# ATtiny20 register map
Vendor: Atmel; File version: 1.0
CPU: other r0p0, little endian, no MPU, no FPU, 4 interrupt priority bits
Registers are 8-bit, read-write, reset 0x0 unless marked. A register's access mark holds for its fields unless they carry their own. Offsets are from the block's base; [hi:lo] are bit positions; {n}, {i} and the like mark numbered series.

## EXINT — External Interrupts
Base 0x00800009
0x00 PCMSK0 — Pin Change Mask Register 0
  [7:0] PCINT — Pin Change Enable Masks
0x01 PCMSK1 — Pin Change Mask Register 1
  [3:0] PCINT — Pin Change Enable Masks
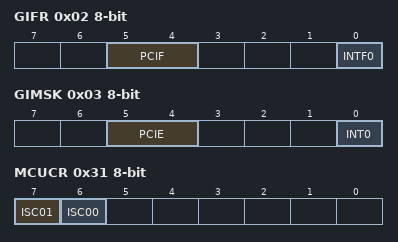
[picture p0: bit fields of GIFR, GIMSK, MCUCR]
0x02 GIFR — General Interrupt Flag Register
  [5:4] PCIF — Pin Change Interrupt Flags
  [0] INTF0 — External Interrupt Flag 0
0x03 GIMSK — General Interrupt Mask Register
  [5:4] PCIE — Pin Change Interrupt Enables
  [0] INT0 — External Interrupt Request 0 Enable
0x31 MCUCR — MCU Control Register
  [7] ISC01 — Interrupt Sense Control 0 Bit 1
  [6] ISC00 — Interrupt Sense Control 0 Bit 0
    0=LOW_LEVEL_OF_INTX; 1=ANY_LOGICAL_CHANGE_ON_INTX

## PORTA — I/O Port
Base 0x00800000
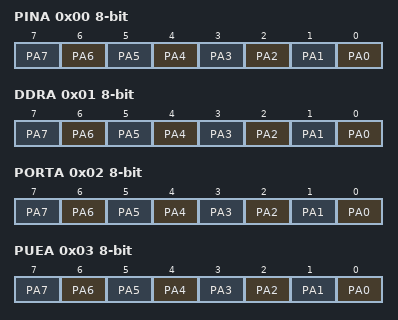
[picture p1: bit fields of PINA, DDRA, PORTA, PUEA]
0x00 PINA — Port A Input Pins
  [n] PA{n} (n=0..7) — Pin A{n}
0x01 DDRA — Data Direction Register, Port A
  [n] PA{n} (n=0..7) — Pin A{n}
0x02 PORTA — Port A Data Register
  [n] PA{n} (n=0..7) — Pin A{n}
0x03 PUEA — Pull-up Enable Control Register
  [n] PA{n} (n=0..7) — Pin A{n}
0x08 PORTCR — Port Control Register
  [0] BBMA — Break-Before-Make Mode Enable

## PORTB — I/O Port
Base 0x00800004
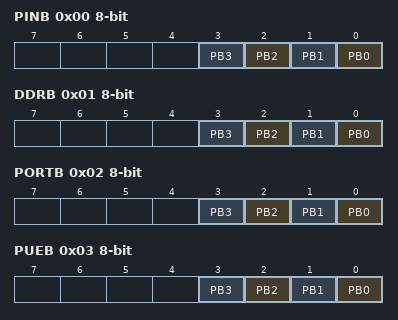
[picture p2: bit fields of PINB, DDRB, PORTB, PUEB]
0x00 PINB — Port B Data register
  [n] PB{n} (n=0..3) — Pin B{n}
0x01 DDRB — Data Direction Register, Port B
  [n] PB{n} (n=0..3) — Pin B{n}
0x02 PORTB — Input Pins, Port B
  [n] PB{n} (n=0..3) — Pin B{n}
0x03 PUEB — Pull-up Enable Control Register
  [n] PB{n} (n=0..3) — Pin B{n}
0x04 PORTCR — Port Control Register
  [1] BBMB — Break-Before-Make Mode Enable

## SPI — Serial Peripheral Interface
Base 0x0080002E
0x00 SPDR — SPI Data Register
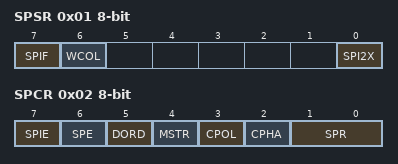
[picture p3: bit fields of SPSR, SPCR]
0x01 SPSR — SPI Status Register
  [7] SPIF — SPI Interrupt Flag
  [6] WCOL — Write Collision Flag
  [0] SPI2X — Double SPI Speed Bit
0x02 SPCR — SPI Control Register
  [7] SPIE — SPI Interrupt Enable
  [6] SPE — SPI Enable
  [5] DORD — Data Order
  [4] MSTR — Master/Slave Select
  [3] CPOL — Clock polarity
  [2] CPHA — Clock Phase
  [1:0] SPR — SPI Clock Rate Selects
    0=FCL_4; 1=FCL_16; 2=FCL_64; 3=FCL_128

## TC0 — Timer/Counter, 8-bit
Base 0x00800015
0x00 OCR0B — Timer/Counter0 Output Compare Register
0x01 OCR0A — Timer/Counter0 Output Compare Register
0x02 TCNT0 — Timer/Counter0
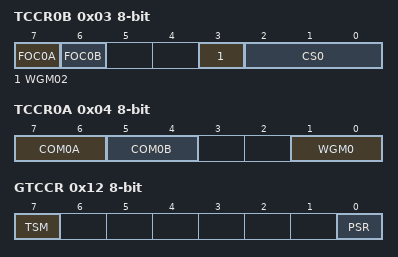
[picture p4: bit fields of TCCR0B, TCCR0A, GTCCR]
0x03 TCCR0B — Timer/Counter 0 Control Register B
  [7] FOC0A — Force Output Compare A
  [6] FOC0B — Force Output Compare B
  [3] WGM02 — Waveform Generation Mode
  [2:0] CS0 — Clock Select
    0=NO_CLOCK_SOURCE_STOPPED; 1=RUNNING_NO_PRESCALING; 2=RUNNING_CLK_8; 3=RUNNING_CLK_64; 4=RUNNING_CLK_256; 5=RUNNING_CLK_1024; 6=RUNNING_EXTCLK_TN_FALLING_EDGE; 7=RUNNING_EXTCLK_TN_RISING_EDGE
0x04 TCCR0A — Timer/Counter 0 Control Register A
  [7:6] COM0A — Compare Output Mode for Channel A bits
  [5:4] COM0B — Compare Output Mode for Channel B bits
  [1:0] WGM0 — Waveform Generation Mode
0x10 TIFR — Overflow Interrupt Enable
  [7] ICF1 — Input Capture Flag
  [5] OCF1B — Timer Output Compare Flag 1B
  [4] OCF1A — Timer Output Compare Flag 1A
  [2] OCF0B — Output Compare Flag 0 B
  [1] OCF0A — Output Compare Flag 0 A
  [3:0] TOV — Timer Overflow Flag
0x11 TIMSK — Timer Interrupt Mask Register
  [7] ICIE1 — Input Capture Interrupt Enable
  [5] OCIE1B — Output Compare B Match Interrupt Enable
  [4] OCIE1A — Output Compare A Match Interrupt Enable
  [2] OCIE0B — Timer/Counter Output Compare Match B Interrupt Enable
  [1] OCIE0A — Timer/Counter0 Output Compare Match A Interrupt Enable
  [3:0] TOIE — Overflow Interrupt Enable
0x12 GTCCR — General Timer/Counter Control Register
  [7] TSM — Timer Synchronization Mode
  [0] PSR — Prescaler Reset

## TC1 — Timer/Counter, 16-bit
Base 0x0080001A
0x00 ICR1 16-bit (reset mask 0xFF) — Input Capture Register Bytes
0x02 OCR1B 16-bit (reset mask 0xFF) — Timer/Counter1 Output Compare Register B
0x04 OCR1A 16-bit (reset mask 0xFF) — Timer/Counter 1 Output Compare Register A
0x06 TCNT1 16-bit (reset mask 0xFF) — Timer/Counter1
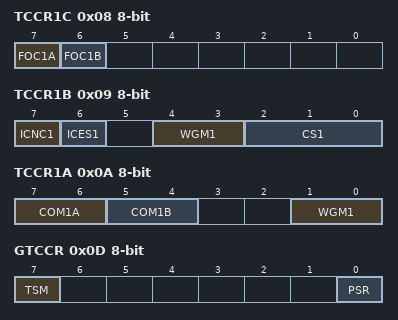
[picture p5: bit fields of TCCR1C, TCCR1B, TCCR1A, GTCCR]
0x08 TCCR1C — Timer/Counter1 Control Register C
  [7] FOC1A — Force Output Compare for channel A
  [6] FOC1B — Force Output Compare for channel B
0x09 TCCR1B — Timer/Counter1 Control Register B
  [7] ICNC1 — Input Capture 1 Noise Canceler
  [6] ICES1 — Input Capture 1 Edge Select
  [4:3] WGM1 — Waveform Generation Mode
  [2:0] CS1 — Clock Select1 bits
    0=NO_CLOCK_SOURCE_STOPPED; 1=RUNNING_NO_PRESCALING; 2=RUNNING_CLK_8; 3=RUNNING_CLK_64; 4=RUNNING_CLK_256; 5=RUNNING_CLK_1024; 6=RUNNING_EXTCLK_TN_FALLING_EDGE; 7=RUNNING_EXTCLK_TN_RISING_EDGE
0x0A TCCR1A — Timer/Counter1 Control Register A
  [7:6] COM1A — Compare Output Mode 1A, bits
  [5:4] COM1B — Compare Output Mode 1B, bits
  [1:0] WGM1 — Waveform Generation Mode Bits
0x0B TIFR — Overflow Interrupt Enable
  [7] ICF1 — Input Capture Flag
  [5] OCF1B — Timer Output Compare Flag 1B
  [4] OCF1A — Timer Output Compare Flag 1A
  [2] OCF0B — Output Compare Flag 0 B
  [1] OCF0A — Output Compare Flag 0 A
  [3:0] TOV — Timer Overflow Flag
0x0C TIMSK — Timer Interrupt Mask Register
  [7] ICIE1 — Input Capture Interrupt Enable
  [5] OCIE1B — Output Compare B Match Interrupt Enable
  [4] OCIE1A — Output Compare A Match Interrupt Enable
  [2] OCIE0B — Timer/Counter Output Compare Match B Interrupt Enable
  [1] OCIE0A — Timer/Counter0 Output Compare Match A Interrupt Enable
  [3:0] TOIE — Overflow Interrupt Enable
0x0D GTCCR — General Timer/Counter Control Register
  [7] TSM — Timer Synchronization Mode
  [0] PSR — Prescaler Reset

## TWI — Two Wire Serial Interface
Base 0x00800028
0x00 TWSD — TWI Slave Data Register (read-only for debugger)
  [7:0] TWSD — TWI slave data bit
0x01 TWSAM — TWI Slave Address Mask Register
0x02 TWSA — TWI Slave Address Register (read-only for debugger)
  [7:0] TWSA — TWI slave address bit
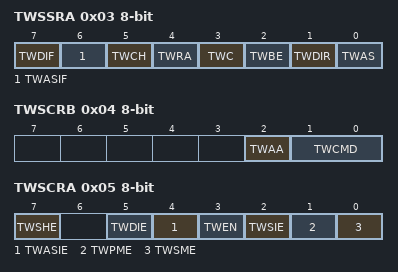
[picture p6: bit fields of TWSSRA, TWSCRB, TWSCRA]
0x03 TWSSRA — TWI Slave Status Register A
  [7] TWDIF — TWI Data Interrupt Flag
  [6] TWASIF — TWI Address/Stop Interrupt Flag
  [5] TWCH — TWI Clock Hold
  [4] TWRA — TWI Receive Acknowledge
  [3] TWC — TWI Collision
  [2] TWBE — TWI Bus Error
  [1] TWDIR — TWI Read/Write Direction
  [0] TWAS — TWI Address or Stop
0x04 TWSCRB — TWI Slave Control Register B
  [2] TWAA — TWI Acknowledge Action
  [1:0] TWCMD
0x05 TWSCRA — TWI Slave Control Register A
  [7] TWSHE — TWI SDA Hold Time Enable
  [5] TWDIE — TWI Data Interrupt Enable
  [4] TWASIE — TWI Address/Stop Interrupt Enable
  [3] TWEN — Two-Wire Interface Enable
  [2] TWSIE — TWI Stop Interrupt Enable
  [1] TWPME — TWI Promiscuous Mode Enable
  [0] TWSME — TWI Smart Mode Enable

## WDT — Watchdog Timer
Base 0x00800031
0x00 WDTCSR — Watchdog Timer Control and Status Register
  [7] WDIF — Watchdog Timer Interrupt Flag
  [6] WDIE — Watchdog Timer Interrupt Enable
  [3] WDE — Watch Dog Enable
  [5:0] WDP — Watchdog Timer Prescaler Bits
    0=OSCILLATOR_CYCLES_2K; 1=OSCILLATOR_CYCLES_4K; 2=OSCILLATOR_CYCLES_8K; 3=OSCILLATOR_CYCLES_16K; 4=OSCILLATOR_CYCLES_32K; 5=OSCILLATOR_CYCLES_64K; 6=OSCILLATOR_CYCLES_128K; 7=OSCILLATOR_CYCLES_256K
